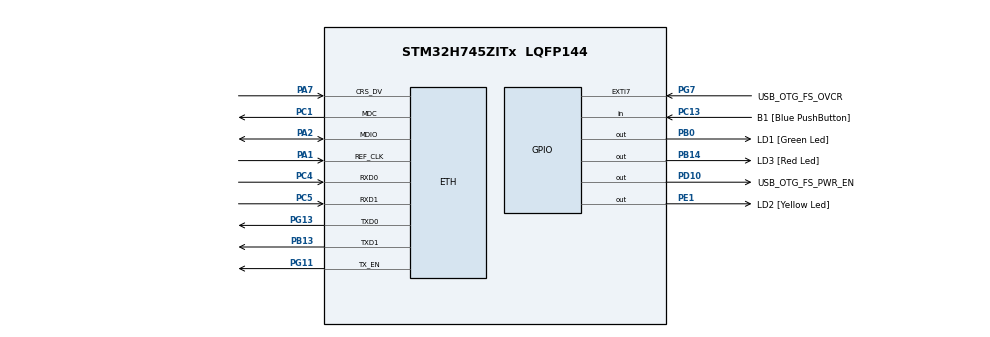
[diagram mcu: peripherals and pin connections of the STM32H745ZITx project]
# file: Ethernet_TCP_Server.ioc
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CORTEX_M7.AccessPermission-Cortex_Memory_Protection_Unit_Region0_Settings=MPU_REGION_FULL_ACCESS
CORTEX_M7.AccessPermission-Cortex_Memory_Protection_Unit_Region1_Settings=MPU_REGION_FULL_ACCESS
CORTEX_M7.BaseAddress-Cortex_Memory_Protection_Unit_Region0_Settings=0x30040000
CORTEX_M7.BaseAddress-Cortex_Memory_Protection_Unit_Region1_Settings=0x30040000
CORTEX_M7.CPU_DCache=Enabled
CORTEX_M7.CPU_ICache=Enabled
CORTEX_M7.DisableExec-Cortex_Memory_Protection_Unit_Region0_Settings=MPU_INSTRUCTION_ACCESS_DISABLE
CORTEX_M7.DisableExec-Cortex_Memory_Protection_Unit_Region1_Settings=MPU_INSTRUCTION_ACCESS_DISABLE
CORTEX_M7.Enable-Cortex_Memory_Protection_Unit_Region0_Settings=MPU_REGION_ENABLE
CORTEX_M7.Enable-Cortex_Memory_Protection_Unit_Region1_Settings=MPU_REGION_ENABLE
CORTEX_M7.IsBufferable-Cortex_Memory_Protection_Unit_Region1_Settings=MPU_ACCESS_BUFFERABLE
CORTEX_M7.IsShareable-Cortex_Memory_Protection_Unit_Region1_Settings=MPU_ACCESS_SHAREABLE
CORTEX_M7.MPU_Control=MPU_PRIVILEGED_DEFAULT
CORTEX_M7.Size-Cortex_Memory_Protection_Unit_Region0_Settings=MPU_REGION_SIZE_32KB
CORTEX_M7.Size-Cortex_Memory_Protection_Unit_Region1_Settings=MPU_REGION_SIZE_256B
CORTEX_M7.TypeExtField-Cortex_Memory_Protection_Unit_Region0_Settings=MPU_TEX_LEVEL1
CortexM4.IPs=FATFS_M4\:I,FREERTOS_M4\:I,IWDG2\:I,RCC,WWDG2\:I,DMA,BDMA,MDMA,NVIC2\:I,USART3,ETH,DEBUG,PDM2PCM_M4\:I,PWR,RESMGR_UTILITY,SYS_M4\:I,USB_DEVICE_M4\:I,USB_HOST_M4\:I,CORTEX_M4\:I,GPIO,OPENAMP_M4\:I,VREFBUF
CortexM7.IPs=FATFS_M7\:I,FREERTOS_M7\:I,IWDG1\:I,RCC\:I,WWDG1\:I,DMA\:I,BDMA\:I,MDMA\:I,NVIC1\:I,SYS\:I,USART3\:I,USB_OTG_FS\:I,ETH\:I,CORTEX_M7\:I,DEBUG\:I,PDM2PCM_M7\:I,PWR\:I,RESMGR_UTILITY\:I,USB_DEVICE_M7\:I,USB_HOST_M7\:I,GPIO\:I,OPENAMP_M7\:I,VREFBUF\:I,LWIP\:I,TIM3\:I
ETH.MediaInterface=HAL_ETH_RMII_MODE
FREERTOS_M7.Tasks01=defaultTask,0,256,StartDefaultTask,Default,NULL,Dynamic,NULL,NULL
LWIP.BSP.number=1
LWIP.GATEWAY_ADDRESS=192.168.001.100
LWIP.IP_ADDRESS=192.168.001.001
LWIP.LWIP_DHCP=0
LWIP.MEM_SIZE=16360
LWIP.NETMASK_ADDRESS=255.255.255.000
LWIP.Version=v2.1.2_Cube
LWIP0.BSP.STBoard=false
LWIP0.BSP.api=BSP_COMPONENT_DRIVER
LWIP0.BSP.component=LAN8742
LWIP0.BSP.instance=LAN8742
LWIP0.BSP.name=Driver_PHY
LWIP0.BSP.semaphore=S_LAN8742
LWIP0.BSP.solution=LAN8742
Mcu.Family=STM32H7
Mcu.Name=STM32H745ZITx
Mcu.Package=LQFP144
NVIC1.ETH_IRQn=true\:5\:0\:true\:false\:true\:true\:true\:true\:true
NVIC1.PriorityGroup=NVIC_PRIORITYGROUP_4
NVIC1.TIM3_IRQn=true\:15\:0\:false\:false\:true\:false\:false\:true\:true
NVIC1.TimeBase=TIM3_IRQn
NVIC1.TimeBaseIP=TIM3
NVIC2.PriorityGroup=NVIC_PRIORITYGROUP_4
PA1.GPIO_Speed=GPIO_SPEED_FREQ_VERY_HIGH
PA1.Mode=RMII
PA1.PinAttribute=CortexM7
PA1.Signal=ETH_REF_CLK
PA11.PinAttribute=CortexM7
PA11.Signal=USB_OTG_FS_DM
PA12.PinAttribute=CortexM7
PA12.Signal=USB_OTG_FS_DP
PA2.GPIO_Speed=GPIO_SPEED_FREQ_VERY_HIGH
PA2.Mode=RMII
PA2.PinAttribute=CortexM7
PA2.Signal=ETH_MDIO
PA7.GPIO_Speed=GPIO_SPEED_FREQ_VERY_HIGH
PA7.Mode=RMII
PA7.PinAttribute=CortexM7
PA7.Signal=ETH_CRS_DV
PA8.PinAttribute=CortexM7
PA8.Signal=USB_OTG_FS_SOF
PA9.PinAttribute=CortexM7
PA9.Signal=USB_OTG_FS_VBUS
PB0.GPIO_Label=LD1 [Green Led]
PB0.PinAttribute=Free
PB0.Signal=GPIO_Output
PB13.GPIO_Speed=GPIO_SPEED_FREQ_VERY_HIGH
PB13.Mode=RMII
PB13.PinAttribute=CortexM7
PB13.Signal=ETH_TXD1
PB14.GPIO_Label=LD3 [Red Led]
PB14.PinAttribute=Free
PB14.Signal=GPIO_Output
PC1.GPIO_Speed=GPIO_SPEED_FREQ_VERY_HIGH
PC1.Mode=RMII
PC1.PinAttribute=CortexM7
PC1.Signal=ETH_MDC
PC13.GPIO_Label=B1 [Blue PushButton]
PC13.PinAttribute=Free
PC13.Signal=GPIO_Input
PC14-OSC32_IN\ (OSC32_IN).PinAttribute=CortexM7
PC14-OSC32_IN\ (OSC32_IN).Signal=RCC_OSC32_IN
PC15-OSC32_OUT\ (OSC32_OUT).PinAttribute=CortexM7
PC15-OSC32_OUT\ (OSC32_OUT).Signal=RCC_OSC32_OUT
PC4.GPIO_Speed=GPIO_SPEED_FREQ_VERY_HIGH
PC4.Mode=RMII
PC4.PinAttribute=CortexM7
PC4.Signal=ETH_RXD0
PC5.GPIO_Speed=GPIO_SPEED_FREQ_VERY_HIGH
PC5.Mode=RMII
PC5.PinAttribute=CortexM7
PC5.Signal=ETH_RXD1
PD10.GPIO_Label=USB_OTG_FS_PWR_EN
PD10.PinAttribute=Free
PD10.Signal=GPIO_Output
PD8.GPIO_Label=STLINK_RX
PD8.PinAttribute=CortexM7
PD8.Signal=USART3_TX
PD9.GPIO_Label=STLINK_TX
PD9.PinAttribute=CortexM7
PD9.Signal=USART3_RX
PE1.GPIO_Label=LD2 [Yellow Led]
PE1.PinAttribute=Free
PE1.Signal=GPIO_Output
PG11.GPIO_Speed=GPIO_SPEED_FREQ_VERY_HIGH
PG11.Mode=RMII
PG11.PinAttribute=CortexM7
PG11.Signal=ETH_TX_EN
PG13.GPIO_Speed=GPIO_SPEED_FREQ_VERY_HIGH
PG13.Mode=RMII
PG13.PinAttribute=CortexM7
PG13.Signal=ETH_TXD0
PG7.GPIO_Label=USB_OTG_FS_OVCR
PG7.PinAttribute=Free
PG7.Signal=GPXTI7
PH0-OSC_IN\ (PH0).Mode=HSE-External-Clock-Source
PH0-OSC_IN\ (PH0).PinAttribute=CortexM7
PH0-OSC_IN\ (PH0).Signal=RCC_OSC_IN
PH1-OSC_OUT\ (PH1).PinAttribute=CortexM7
PH1-OSC_OUT\ (PH1).Signal=RCC_OSC_OUT
ProjectManager.HeapSize=M4-0x200,M7-0x200
ProjectManager.StackSize=M4-0x400,M7-0x400
ProjectManager.TargetToolchain=STM32CubeIDE
RCC.ADCFreq_Value=129000000
RCC.APB1Freq_Value=100000000
RCC.APB2Freq_Value=100000000
RCC.APB3Freq_Value=100000000
RCC.APB4Freq_Value=100000000
RCC.CortexFreq_Value=400000000
RCC.D1PPRE=RCC_APB3_DIV2
RCC.D2PPRE1=RCC_APB1_DIV2
RCC.D2PPRE2=RCC_APB2_DIV2
RCC.D3PPRE=RCC_APB4_DIV2
RCC.DIVM1=4
RCC.DIVM3=22
RCC.DIVN1=50
RCC.DIVN3=169
RCC.DIVQ3=4
RCC.HCLKFreq_Value=200000000
RCC.HPRE=RCC_HCLK_DIV2
RCC.PLL2FRACN=0
RCC.PLL3FRACN=0
RCC.PLLFRACN=0
RCC.SYSCLKFreq_VALUE=400000000
RCC.SYSCLKSource=RCC_SYSCLKSOURCE_PLLCLK
RCC.SupplySource=PWR_DIRECT_SMPS_SUPPLY
RCC.USBCLockSelection=RCC_USBCLKSOURCE_PLL3
RCC.USBFreq_Value=122909090.9090909
VP_FREERTOS_M7_VS_CMSIS_V1.Mode=CMSIS_V1
VP_LWIP_VS_Enabled.Mode=Enabled
VP_SYS_M4_VS_Systick.Mode=SysTick
VP_SYS_VS_tim3.Mode=TIM3
board=NUCLEO-H745ZI-Q

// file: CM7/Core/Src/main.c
/* USER CODE BEGIN Header */
/**
  ******************************************************************************
  * @file           : main.c
  * @brief          : Main program body
  ******************************************************************************
  * @attention
  *
  * Copyright (c) 2022 STMicroelectronics.
  * All rights reserved.
  *
  * This software is licensed under terms that can be found in the LICENSE file
  * in the root directory of this software component.
  * If no LICENSE file comes with this software, it is provided AS-IS.
  *
  ******************************************************************************
  */
/* USER CODE END Header */
#include "main.h"
#include "cmsis_os.h"
#include "lwip.h"

/* USER CODE BEGIN Includes */
#include "tcpServerRAW.h"
/* USER CODE END Includes */

/* USER CODE BEGIN PD */

#ifndef HSEM_ID_0
#define HSEM_ID_0 (0U) /* HW semaphore 0*/
#endif
/* USER CODE END PD */

osThreadId defaultTaskHandle;

void SystemClock_Config(void);
static void MPU_Config(void);
static void MX_GPIO_Init(void);
void StartDefaultTask(void const * argument);

int main(void)
{
/* USER CODE BEGIN Boot_Mode_Sequence_0 */
  int32_t timeout;
/* USER CODE END Boot_Mode_Sequence_0 */

  /* MPU Configuration--------------------------------------------------------*/
  MPU_Config();

  /* Enable I-Cache---------------------------------------------------------*/
  SCB_EnableICache();

  /* Enable D-Cache---------------------------------------------------------*/
  SCB_EnableDCache();

/* USER CODE BEGIN Boot_Mode_Sequence_1 */
  /* Wait until CPU2 boots and enters in stop mode or timeout*/
  timeout = 0xFFFF;
  while((__HAL_RCC_GET_FLAG(RCC_FLAG_D2CKRDY) != RESET) && (timeout-- > 0));
  if ( timeout < 0 )
  {
  Error_Handler();
  }
/* USER CODE END Boot_Mode_Sequence_1 */
  /* MCU Configuration--------------------------------------------------------*/

  /* Reset of all peripherals, Initializes the Flash interface and the Systick. */
  HAL_Init();

  /* Configure the system clock */
  SystemClock_Config();
/* USER CODE BEGIN Boot_Mode_Sequence_2 */
/* When system initialization is finished, Cortex-M7 will release Cortex-M4 by means of
HSEM notification */
/*HW semaphore Clock enable*/
__HAL_RCC_HSEM_CLK_ENABLE();
/*Take HSEM */
HAL_HSEM_FastTake(HSEM_ID_0);
/*Release HSEM in order to notify the CPU2(CM4)*/
HAL_HSEM_Release(HSEM_ID_0,0);
/* wait until CPU2 wakes up from stop mode */
timeout = 0xFFFF;
while((__HAL_RCC_GET_FLAG(RCC_FLAG_D2CKRDY) == RESET) && (timeout-- > 0));
if ( timeout < 0 )
{
Error_Handler();
}
/* USER CODE END Boot_Mode_Sequence_2 */

  /* Initialize all configured peripherals */
  MX_GPIO_Init();

  /* Create the thread(s) */
  /* definition and creation of defaultTask */
  osThreadDef(defaultTask, StartDefaultTask, osPriorityNormal, 0, 256);
  defaultTaskHandle = osThreadCreate(osThread(defaultTask), NULL);

  /* Start scheduler */
  osKernelStart();

  /* We should never get here as control is now taken by the scheduler */
  /* Infinite loop */
  while (1)
  {

  }
}

void SystemClock_Config(void)
{
  RCC_OscInitTypeDef RCC_OscInitStruct = {0};
  RCC_ClkInitTypeDef RCC_ClkInitStruct = {0};

  /** Supply configuration update enable
  */
  HAL_PWREx_ConfigSupply(PWR_DIRECT_SMPS_SUPPLY);

  /** Configure the main internal regulator output voltage
  */
  __HAL_PWR_VOLTAGESCALING_CONFIG(PWR_REGULATOR_VOLTAGE_SCALE1);

  while(!__HAL_PWR_GET_FLAG(PWR_FLAG_VOSRDY)) {}

  /** Initializes the RCC Oscillators according to the specified parameters
  * in the RCC_OscInitTypeDef structure.
  */
  RCC_OscInitStruct.OscillatorType = RCC_OSCILLATORTYPE_HSI;
  RCC_OscInitStruct.HSIState = RCC_HSI_DIV1;
  RCC_OscInitStruct.HSICalibrationValue = RCC_HSICALIBRATION_DEFAULT;
  RCC_OscInitStruct.PLL.PLLState = RCC_PLL_ON;
  RCC_OscInitStruct.PLL.PLLSource = RCC_PLLSOURCE_HSI;
  RCC_OscInitStruct.PLL.PLLM = 4;
  RCC_OscInitStruct.PLL.PLLN = 50;
  RCC_OscInitStruct.PLL.PLLP = 2;
  RCC_OscInitStruct.PLL.PLLQ = 2;
  RCC_OscInitStruct.PLL.PLLR = 2;
  RCC_OscInitStruct.PLL.PLLRGE = RCC_PLL1VCIRANGE_3;
  RCC_OscInitStruct.PLL.PLLVCOSEL = RCC_PLL1VCOWIDE;
  RCC_OscInitStruct.PLL.PLLFRACN = 0;
  if (HAL_RCC_OscConfig(&RCC_OscInitStruct) != HAL_OK)
  {
    Error_Handler();
  }

  /** Initializes the CPU, AHB and APB buses clocks
  */
  RCC_ClkInitStruct.ClockType = RCC_CLOCKTYPE_HCLK|RCC_CLOCKTYPE_SYSCLK
                              |RCC_CLOCKTYPE_PCLK1|RCC_CLOCKTYPE_PCLK2
                              |RCC_CLOCKTYPE_D3PCLK1|RCC_CLOCKTYPE_D1PCLK1;
  RCC_ClkInitStruct.SYSCLKSource = RCC_SYSCLKSOURCE_PLLCLK;
  RCC_ClkInitStruct.SYSCLKDivider = RCC_SYSCLK_DIV1;
  RCC_ClkInitStruct.AHBCLKDivider = RCC_HCLK_DIV2;
  RCC_ClkInitStruct.APB3CLKDivider = RCC_APB3_DIV2;
  RCC_ClkInitStruct.APB1CLKDivider = RCC_APB1_DIV2;
  RCC_ClkInitStruct.APB2CLKDivider = RCC_APB2_DIV2;
  RCC_ClkInitStruct.APB4CLKDivider = RCC_APB4_DIV2;

  if (HAL_RCC_ClockConfig(&RCC_ClkInitStruct, FLASH_LATENCY_2) != HAL_OK)
  {
    Error_Handler();
  }
}

static void MX_GPIO_Init(void)
{
  GPIO_InitTypeDef GPIO_InitStruct = {0};

  /* GPIO Ports Clock Enable */
  __HAL_RCC_GPIOC_CLK_ENABLE();
  __HAL_RCC_GPIOH_CLK_ENABLE();
  __HAL_RCC_GPIOA_CLK_ENABLE();
  __HAL_RCC_GPIOB_CLK_ENABLE();
  __HAL_RCC_GPIOD_CLK_ENABLE();
  __HAL_RCC_GPIOG_CLK_ENABLE();

  /*Configure GPIO pins : PD8 PD9 */
  GPIO_InitStruct.Pin = GPIO_PIN_8|GPIO_PIN_9;
  GPIO_InitStruct.Mode = GPIO_MODE_AF_PP;
  GPIO_InitStruct.Pull = GPIO_NOPULL;
  GPIO_InitStruct.Speed = GPIO_SPEED_FREQ_LOW;
  GPIO_InitStruct.Alternate = GPIO_AF7_USART3;
  HAL_GPIO_Init(GPIOD, &GPIO_InitStruct);

  /*Configure GPIO pins : PA8 PA11 PA12 */
  GPIO_InitStruct.Pin = GPIO_PIN_8|GPIO_PIN_11|GPIO_PIN_12;
  GPIO_InitStruct.Mode = GPIO_MODE_AF_PP;
  GPIO_InitStruct.Pull = GPIO_NOPULL;
  GPIO_InitStruct.Speed = GPIO_SPEED_FREQ_LOW;
  GPIO_InitStruct.Alternate = GPIO_AF10_OTG1_FS;
  HAL_GPIO_Init(GPIOA, &GPIO_InitStruct);

}

void StartDefaultTask(void const * argument)
{
  /* init code for LWIP */
  MX_LWIP_Init();
  /* USER CODE BEGIN 5 */
  tcp_server_init();
  /* Infinite loop */
  for(;;)
  {
    osDelay(1);
  }
  /* USER CODE END 5 */
}

/* MPU Configuration */

void MPU_Config(void)
{
  MPU_Region_InitTypeDef MPU_InitStruct = {0};

  /* Disables the MPU */
  HAL_MPU_Disable();

  /** Initializes and configures the Region and the memory to be protected
  */
  MPU_InitStruct.Enable = MPU_REGION_ENABLE;
  MPU_InitStruct.Number = MPU_REGION_NUMBER0;
  MPU_InitStruct.BaseAddress = 0x30040000;
  MPU_InitStruct.Size = MPU_REGION_SIZE_32KB;
  MPU_InitStruct.SubRegionDisable = 0x0;
  MPU_InitStruct.TypeExtField = MPU_TEX_LEVEL1;
  MPU_InitStruct.AccessPermission = MPU_REGION_FULL_ACCESS;
  MPU_InitStruct.DisableExec = MPU_INSTRUCTION_ACCESS_DISABLE;
  MPU_InitStruct.IsShareable = MPU_ACCESS_NOT_SHAREABLE;
  MPU_InitStruct.IsCacheable = MPU_ACCESS_NOT_CACHEABLE;
  MPU_InitStruct.IsBufferable = MPU_ACCESS_NOT_BUFFERABLE;

  HAL_MPU_ConfigRegion(&MPU_InitStruct);

  /** Initializes and configures the Region and the memory to be protected
  */
  MPU_InitStruct.Number = MPU_REGION_NUMBER1;
  MPU_InitStruct.Size = MPU_REGION_SIZE_256B;
  MPU_InitStruct.TypeExtField = MPU_TEX_LEVEL0;
  MPU_InitStruct.IsShareable = MPU_ACCESS_SHAREABLE;
  MPU_InitStruct.IsBufferable = MPU_ACCESS_BUFFERABLE;

  HAL_MPU_ConfigRegion(&MPU_InitStruct);
  /* Enables the MPU */
  HAL_MPU_Enable(MPU_PRIVILEGED_DEFAULT);

}

void HAL_TIM_PeriodElapsedCallback(TIM_HandleTypeDef *htim)
{
  if (htim->Instance == TIM3) {
    HAL_IncTick();
  }
}

void Error_Handler(void)
{
  __disable_irq();
  while (1)
  {
  }
}
